# STM32MP23_CM33 register map
File version: 1.2
CPU: CM33 r0p1, little endian, MPU, FPU, vendor SysTick, 8 interrupt priority bits
Registers are 32-bit, read-write, reset 0x0 unless marked. A register's access mark holds for its fields unless they carry their own. Offsets are from the block's base; [hi:lo] are bit positions; {n}, {i} and the like mark numbered series; 'fields as' and 'values as' point back to an identical list.

## PWR — PWR register block
Base 0x44210000
Same registers: PWR_S 0x54210000
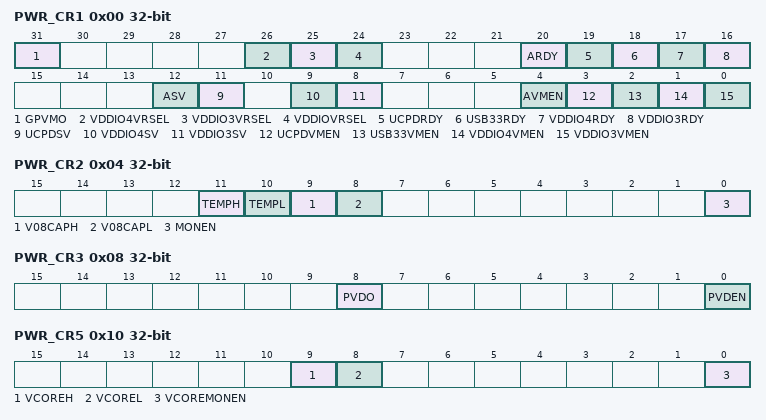
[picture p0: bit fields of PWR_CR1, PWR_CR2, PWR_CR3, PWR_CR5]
0x00 PWR_CR1 — PWR control register 1
  [31] GPVMO ro — Global peripheral voltage monitor output
    0=All enabled/valid independent power supplies are equal or higher than PVM threshold; 1=At least one enabled/valid independent power supply is lower than PVM threshold
  [26] VDDIO4VRSEL — VDDIO4 I/O voltage range selection
    0=3; 1=1
  [25] VDDIO3VRSEL — VDDIO3 I/O voltage range selection
    0=3; 1=1
  [24] VDDIOVRSEL — VDD I/O voltage range selection
    0=3; 1=1
  [20] ARDY ro — Vless thansub>DDA18ADC less than/sub>ready
    0=Vless thansub>DDA18ADCless than/sub> is below the threshold of the Vless thansub>DDA18ADCless than/sub> voltage monitor; 1=Vless thansub>DDA18ADCless than/sub> is equal or above the threshold of the Vless thansub>DDA18ADCless than/sub> voltage monitor
  [19] UCPDRDY ro — Vless thansub>DD33UCPD less than/sub>ready
    0=Vless thansub>DD33UCPDless than/sub> is below the threshold of the UCPD voltage monitor; 1=Vless thansub>DD33UCPDless than/sub> is equal or above the threshold of the UCPD voltage monitor
  [18] USB33RDY ro — Vless thansub>DD33USB less than/sub>ready
    0=Vless thansub>DD33USBless than/sub> is below the threshold of the USB33 voltage monitor; 1=Vless thansub>DD33USBless than/sub> is equal or above the threshold of the USB33 voltage monitor
  [17] VDDIO4RDY ro — Vless thansub>DDIO4 less than/sub>ready
    0=Vless thansub>DDIO4less than/sub> is below the threshold of the Vless thansub>DDIO4less than/sub> voltage monitor; 1=Vless thansub>DDIO4less than/sub> is equal or above the threshold of the Vless thansub>DDIO4less than/sub> voltage monitor
  [16] VDDIO3RDY ro — Vless thansub>DDIO3 less than/sub>ready
    0=Vless thansub>DDIO3less than/sub> is below the threshold of the Vless thansub>DDIO3less than/sub> voltage monitor; 1=Vless thansub>DDIO3less than/sub> is equal or above the threshold of the Vless thansub>DDIO3less than/sub> voltage monitor
  [12] ASV — Vless thansub>DDA18ADC less than/sub>independent supply valid
    0=Vless thansub>DDA18ADCless than/sub> is not present; 1=Vless thansub>DDA18ADCless than/sub> is valid
  [11] UCPDSV — Vless thansub>DD33UCPD less than/sub>independent supply valid
    0=Vless thansub>DD33UCPDless than/sub> is not present; 1=Vless thansub>DD33UCPDless than/sub> is valid
  [9] VDDIO4SV — Vless thansub>DDIO4 less than/sub>independent supply valid
    0=Vless thansub>DDIO4less than/sub> is not present; 1=Vless thansub>DDIO4less than/sub> is valid
  [8] VDDIO3SV — Vless thansub>DDIO3 less than/sub>independent supply valid
    0=Vless thansub>DDIO3less than/sub> is not present; 1=Vless thansub>DDIO3less than/sub> is valid
  [4] AVMEN — Vless thansub>DDA18ADC less than/sub>independent ADC voltage monitor enable
    0=Vless thansub>DDA18ADCless than/sub> voltage monitor disabled; 1=Vless thansub>DDA18ADCless than/sub> voltage monitor enabled
  [3] UCPDVMEN — Vless thansub>DD33UCPD less than/sub>independent UCPD voltage monitor enable
    0=Vless thansub>DD33UCPDless than/sub> voltage monitor disabled; 1=Vless thansub>DD33UCPDless than/sub> voltage monitor enabled
  [2] USB33VMEN — Vless thansub>DD33USB less than/sub>independent USB 33 voltage monitor enable
    0=Vless thansub>DD33USBless than/sub> voltage monitor disabled; 1=Vless thansub>DD33USBless than/sub> voltage monitor enabled
  [1] VDDIO4VMEN — Vless thansub>DDIO4 less than/sub>independent voltage monitor enable
    0=Vless thansub>DDIO4less than/sub> voltage monitor r disabled; 1=Vless thansub>DDIO4less than/sub> voltage monitor enabled
  [0] VDDIO3VMEN — Vless thansub>DDIO3 less than/sub>independent voltage monitor enable
    0=Vless thansub>DDIO3less than/sub> voltage monitor disabled; 1=Vless thansub>DDIO3less than/sub> voltage monitor enabled
0x04 PWR_CR2 — PWR control register 2
  [11] TEMPH ro — Monitored temperature level above high threshold
    0=Temperature below high threshold level, or monitor disabled; 1=Temperature equal or above high threshold level
  [10] TEMPL ro — Monitored temperature level above low threshold
    0=Temperature above low threshold level, or monitor disabled; 1=Temperature equal or below low threshold level
  [9] V08CAPH ro — Monitored Vless thansub>08CAPless than/sub> level above high threshold
    0=Vless thansub>08CAPless than/sub> level below high threshold level, or monitor disabled; 1=Vless thansub>08CAPless than/sub> level equal or above high threshold level
  [8] V08CAPL ro — Monitored Vless thansub>08CAPless than/sub> level above low threshold
    0=Vless thansub>08CAPless than/sub> level above low threshold level, or monitor disabled; 1=Vless thansub>08CAPless than/sub> level equal or below low threshold level
  [0] MONEN — Vless thansub>08CAPless than/sub> and temperature monitoring enable
    0=Vless thansub>08CAPless than/sub> and temperature monitoring disabled; 1=Vless thansub>08CAPless than/sub> and temperature monitoring enabled
0x08 PWR_CR3 — PWR control register 3
  [8] PVDO ro — Programmable voltage detector (PVD) output
    0=Voltage level on PVD_IN is equal or higher than the internal Vless thansub>REFINTless than/sub>; 1=Voltage level on PVD_IN is lower than the internal Vless thansub>REFINTless than/sub>
  [0] PVDEN — PVD enable
    0=PVD disabled; 1=PVD enabled
0x10 PWR_CR5 — PWR control register 5
  [9] VCOREH ro — Monitored Vless thansub>DDCOREless than/sub> level above high threshold
    0=Vless thansub>DDCOREless than/sub> level below high threshold level, or monitor disabled; 1=Vless thansub>DDCOREless than/sub> level equal or above high threshold level
  [8] VCOREL ro — Monitored Vless thansub>DDCOREless than/sub> level above low threshold
    0=Vless thansub>DDCOREless than/sub> level above low threshold level, or monitor disabled; 1=Vless thansub>DDCOREless than/sub> level equal or below low threshold level
  [0] VCOREMONEN — Vless thansub>DDCOREless than/sub> monitoring enable
    0=Vless thansub>DDCOREless than/sub> monitoring disabled; 1=Vless thansub>DDCOREless than/sub> monitoring enabled
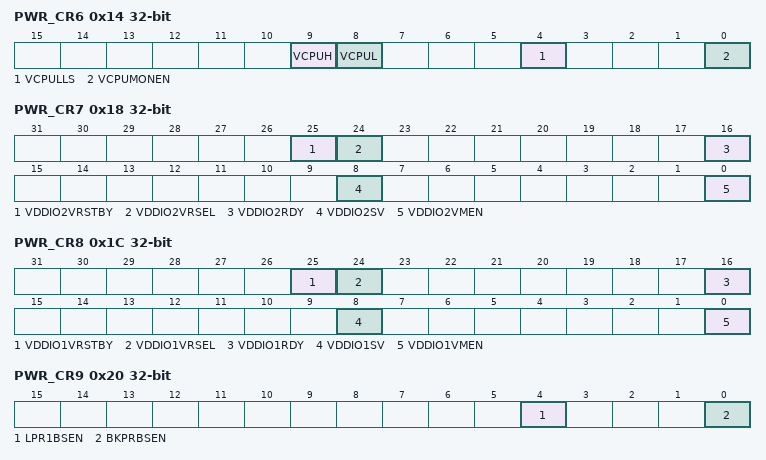
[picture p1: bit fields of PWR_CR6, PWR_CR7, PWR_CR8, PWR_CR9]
0x14 PWR_CR6 — PWR control register 6
  [9] VCPUH ro — Monitored Vless thansub>DDCPUless than/sub> level above high threshold
    0=Vless thansub>DDCPUless than/sub> level below high threshold level, or monitor disabled; 1=Vless thansub>DDCPUless than/sub> level equal or above high threshold level
  [8] VCPUL ro — Monitored Vless thansub>DDCPUless than/sub> level above low threshold
    0=Vless thansub>DDCPUless than/sub> level above low threshold level, or monitor disabled; 1=Vless thansub>DDCPUless than/sub> level equal or below low threshold level
  [4] VCPULLS — Vless thansub>DDCPUless than/sub> voltage detector low level selection
    0=VCPU low-voltage threshold 1 selected; 1=VCPU low-voltage threshold 2 selected (overdrive mode)
  [0] VCPUMONEN — Vless thansub>DDCPUless than/sub> monitoring enable
    0=Vless thansub>DDCPUless than/sub> monitoring disabled; 1=Vless thansub>DDCPUless than/sub> monitoring enabled
0x18 PWR_CR7 — PWR control register 7
  [25] VDDIO2VRSTBY — Vless thansub>DDIO2less than/sub> I/O voltage range Standby mode
    0=VDDIO2VRSEL not retained in Standby mode; 1=VDDIO2VRSEL retained in Standby mode
  [24] VDDIO2VRSEL — Vless thansub>DDIO2less than/sub> I/O voltage range selection
    0=3; 1=1
  [16] VDDIO2RDY ro — Vless thansub>DDIO2 less than/sub>ready
    0=Vless thansub>DDIO2less than/sub> is below the threshold of the Vless thansub>DDIO2less than/sub> voltage monitor; 1=Vless thansub>DDIO2less than/sub> is equal or above the threshold of the Vless thansub>DDIO2less than/sub> voltage monitor
  [8] VDDIO2SV — Vless thansub>DDIO2 less than/sub>Independent supply valid.
    0=Vless thansub>DDIO2less than/sub> is not present; 1=Vless thansub>DDIO2less than/sub> is valid
  [0] VDDIO2VMEN — Vless thansub>DDIO2 less than/sub>independent voltage monitor enable
    0=Vless thansub>DDIO2less than/sub> voltage monitor disabled; 1=Vless thansub>DDIO2less than/sub> voltage monitor enabled
0x1C PWR_CR8 — PWR control register 8
  [25] VDDIO1VRSTBY — Vless thansub>DDIO1less than/sub> I/O voltage range Standby mode
    0=VDDIO1VRSEL not retained in Standby mode; 1=VDDIO1VRSEL bit retained in Standby mode
  [24] VDDIO1VRSEL — Vless thansub>DDIO1less than/sub> I/O voltage range selection
    0=3; 1=1
  [16] VDDIO1RDY ro — Vless thansub>DDIO1 less than/sub>ready
    0=Vless thansub>DDIO1less than/sub> is below the threshold of the Vless thansub>DDIO1less than/sub> voltage monitor; 1=Vless thansub>DDIO1less than/sub> is equal or above the threshold of the Vless thansub>DDIO1less than/sub> voltage monitor
  [8] VDDIO1SV — Vless thansub>DDIO1 less than/sub>independent I/O supply valid
    0=Vless thansub>DDIO1less than/sub> is not present; 1=Vless thansub>DDIO1less than/sub> is valid
  [0] VDDIO1VMEN — Vless thansub>DDOI1 less than/sub>independent I/O voltage monitor enable
    0=Vless thansub>DDIO1less than/sub> voltage monitor disabled; 1=Vless thansub>DDIO1less than/sub> voltage monitor enabled
0x20 PWR_CR9 — PWR control register 9
  [4] LPR1BSEN — LPSRAM 1 backup supply enable
    0=LPSRAM1 backup supply disabled; 1=LPSRAM1 backup supply enabled
  [0] BKPRBSEN — Backup RAM backup supply enable
    0=BKPSRAM backup supply disabled; 1=BKPSRAM backup supply enabled
0x24 PWR_CR10 — PWR control register 10
  [1:0] RETRBSEN — Retention RAM backup supply enable
    0=RETRAM backup supply disabled; 1=RETRAM backup supply enabled in Standby and Vless thansub>BATless than/sub>; 2=RETRAM backup supply enabled only in Standby (memory content lost in Vless thansub>BATless than/sub> mode); 3=RETRAM backup supply enabled only in Standby (memory content lost in Vless thansub>BATless than/sub> mode)
0x28 PWR_CR11 — PWR control register 11
  [0] DDRRETDIS — DDR retention disable
    0=DDR self-refresh retention enabled; 1=DDR self-refresh retention disabled
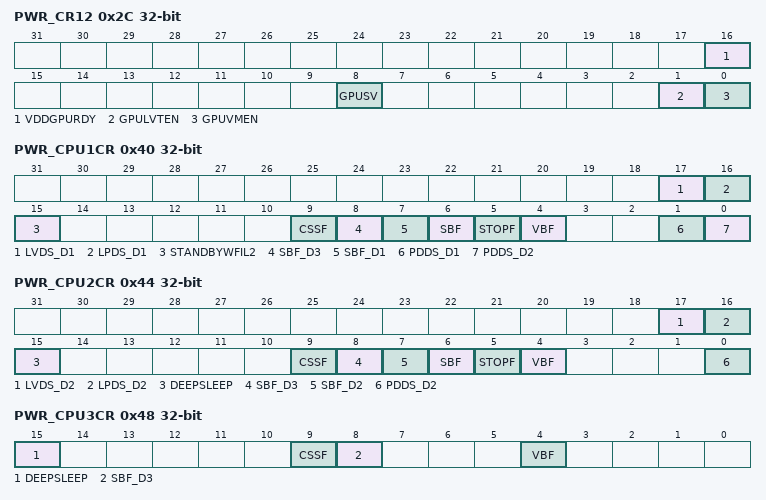
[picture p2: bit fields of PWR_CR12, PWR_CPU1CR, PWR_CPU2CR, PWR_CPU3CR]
0x2C PWR_CR12 — PWR control register 12
  [16] VDDGPURDY ro — Vless thansub>DDGPUless than/sub> ready
    0=Vless thansub>DDGPUless than/sub> is below the threshold of the Vless thansub>DDGPUless than/sub> voltage monitor (or the voltage monitor is disabled); 1=Vless thansub>DDGPUless than/sub> is equal or above the threshold of the Vless thansub>DDGPUless than/sub> voltage monitor
  [8] GPUSV — Vless thansub>DDGPU less than/sub>independent supply valid
    0=Vless thansub>DDGPUless than/sub> is not present; 1=Vless thansub>DDGPUless than/sub> is valid
  [1] GPULVTEN — Vless thansub>DDGPU less than/sub>low-voltage threshold enable
    0=Low-voltage threshold disabled; 1=Low-voltage threshold enabled
  [0] GPUVMEN — Vless thansub>DDGPUless than/sub> independent GPU voltage monitor enable
    0=Vless thansub>DDGPUless than/sub> voltage monitor disabled; 1=Vless thansub>DDGPUless than/sub> voltage monitor enabled
0x38 PWR_BDCR1 — PWR backup domain control register 1
  [0] DBD3P — Disable backup and D3 domains (including LPSRAM1/2/3) write protection
    0=Write access to backup and D3 domains disabled; 1=Write access to backup and D3 domains enabled
0x3C PWR_BDCR2 — PWR backup domain control register 2
  [0] DBP — Disable backup domain write protection
    0=Write access to backup domain disabled; 1=Write access to backup domain enabled
0x40 PWR_CPU1CR — PWR CPU1 control register
  [17] LVDS_D1 — Low-voltage Deepsleep LPLV-Stop mode selection for the D1 domain (DStop3)
    0=LP-Stop mode Vless thansub>DDCPU less than/sub>domainless thansub> less than/sub>supply reset level at same level as Run mode; 1=LPLV-Stop mode Vless thansub>DDCPU less than/sub>domain supply reset level at lower level than Run mode
  [16] LPDS_D1 — low-power Deepsleep Stop mode selection for the D1 domain (DStop2)
    0=Stop mode selected, external regulator kept in main power mode; 1=LP/LPLV-Stop mode selected, external regulator may enter low-power mode (low-power mode selection provided by LVDS_D1)
  [15] STANDBYWFIL2 ro — CPU1 system idle indication
    0=CPU1 system active; 1=CPU1 system idle
  [9] CSSF wo — Clear CPU1 STOPF, SBF_D1/D3, SBF, VBF and CPU2 SBF flags (Always read as 0)
    0=No effect; 1=Clear CPU1 (STOPF, SBF_D1/D3, SBF, VBF) and CPU2 SBF flags
  [8] SBF_D3 — D3 SStandby flag
    0=D3 domain has not been in SStandby mode; 1=D3 domain has been in SStandby mode
  [7] SBF_D1 ro — D1 DStandby flag
    0=D1 domain has not been in DStandby mode; 1=D1 domain has been in DStandby mode
  [6] SBF ro — System Standby flag
    0=System has not been in Standby mode; 1=System has been in Standby mode and system contents has been lost
  [5] STOPF ro — System Stop flag
    0=System has not been in Stop mode; 1=System has been in Stop mode, and the clock system has been stopped
  [4] VBF — Vless thansub>BATless than/sub> mode exit flag
    0=System has not been in Vless thansub>BATless than/sub> mode; 1=System has been in Vless thansub>BATless than/sub> mode
  [1] PDDS_D1 — D1 domain power-down Deepsleep selection
    0=DStop mode kept when CPU1 enters CStop; 1=DStandby mode allowed when CPU1 enters CStop
  [0] PDDS_D2 — D2 domain/system power-down Deepsleep selection
    0=Stop mode kept when CPU1 enters CStop; 1=Standby mode allowed when CPU1 enters CStop
0x44 PWR_CPU2CR — PWR CPU2 control register
  [17] LVDS_D2 — Low-voltage Deepsleep LPLV-Stop mode selection for the D2 domain/system
    0=LP-Stop mode Vless thansub>DDCORE less than/sub>domainless thansub> less than/sub>supply reset level at same level as Run mode; 1=LPLV-Stop mode Vless thansub>DDCORE less than/sub>domain supply reset level at lower level than Run mode
  [16] LPDS_D2 — low-power Deepsleep Stop mode selection for the D2 domain/syste.
    0=Stop mode selected, external regulator kept in main power mode (pwr_lp=1); 1=LP/LPLV-Stop mode selected, external regulator may enter low-power mode (pwr_lp = 0) (low-power mode selection provided by LVDS_D2)
  [15] DEEPSLEEP ro — CPU2 system idle indication
    0=CPU2 system active; 1=CPU2 system idle
  [9] CSSF wo — Clear CPU2 STOPF, SBF_D2/D3, SBF, VBF and CPU1 SBF flags (Always read as 0)
    0=No effect; 1=Clear CPU2 (STOPF, SBF_D2/D3, SBF, VBF) and CPU1 SBF flags
  [8] SBF_D3 — D3 SStandby flag
    values as PWR_CPU1CR.SBF_D3
  [7] SBF_D2 ro — D2 Standby flag
    0=D2 domain has not been in Standby mode; 1=D2 domain has been in Standby mode
  [6] SBF ro — System Standby flag
    0=System has not been in Standby mode; 1=System has been in Standby mode, system contents has been lost
  [5] STOPF ro — System Stop flag
    values as PWR_CPU1CR.STOPF
  [4] VBF — Vless thansub>BATless than/sub> exit flag
    values as PWR_CPU1CR.VBF
  [0] PDDS_D2 — D2 domain/system power-down Deepsleep selection
    0=Stop mode kept when CPU2 enters CStop; 1=Standby mode allowed when CPU2 enters CStop
0x48 PWR_CPU3CR — PWR CPU3 control register
  [15] DEEPSLEEP ro — CPU3 system idle indication
    0=CPU3 active; 1=CPU3 idle
  [9] CSSF wo — Clear CPU3 SBF_D3 and VBF flags (Always read as 0)
    0=No effect; 1=Clear CPU3 SBF_D3 and VBF flags
  [8] SBF_D3 ro — D3 SStandby flag
    values as PWR_CPU1CR.SBF_D3
  [4] VBF ro — Vless thansub>BATless than/sub> exit flag
    values as PWR_CPU1CR.VBF
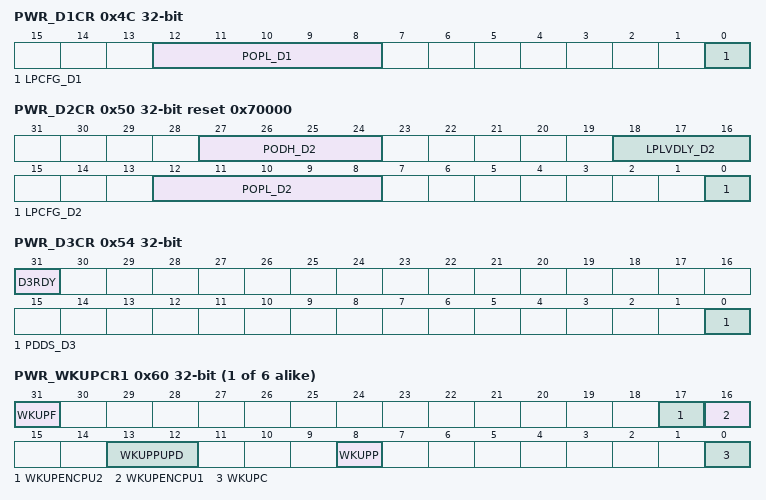
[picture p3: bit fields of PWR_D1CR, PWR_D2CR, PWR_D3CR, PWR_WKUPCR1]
0x4C PWR_D1CR — PWR D1 control register
  [12:8] POPL_D1 — pwr_cpu_on pulse low configuration
    0=No guaranteed minimum low time; 1=~ 1 ms guaranteed minimum low time (1 x 32 LSI cycles); 2=~ 2 ms guaranteed minimum low time (2 x 32 LSI cycles); 31=~ 31 ms guaranteed minimum low time
  [0] LPCFG_D1 — PWR_CPU_ON pin configuration
    0=PWR_CPU_ON pin signals DStandby mode (PWR_CPU_ON=1 in DRun, DStop1/2/3, and=0 in DStandby) (pwr_cpu_on); 1=PWR_CPU_ON pin signals DStandby and DStop2/3 modes (PWR_CPU_ON = 1 in DRun, DStop1, and=0 in DStop2/3 and DStandby) (pwr_cpu_onlp)
0x50 PWR_D2CR reset 0x70000 — PWR D2 control register
  [27:24] PODH_D2 — pwr_on delay high configuration
    0=No delay; 1=~ 1 ms delay (1 x 32 LSI cycles); 2=~ 2 ms delay (2 x 32 LSI cycles); 15=~ 15 ms delay (15 x 32 LSI cycles)
  [18:16] LPLVDLY_D2 — LPLV delay value
    0=~187 us delay (1 x 6 LSI cycles); 1=~375 us delay (2 x 6 LSI cycles); 2=~562 us delay (3 x 6 LSI cycles); 7=~1
  [12:8] POPL_D2 — pwr_on pulse low configuration
    0=No guaranteed minimum low time; 1=~ 1 ms guaranteed minimum low time (1 x 32 LSI cycles); 2=~ 2 ms guaranteed minimum low time (2 x 32 LSI cycles); 31=~ 31 ms guaranteed minimum low time (31 x 32 LSI cycles)
  [0] LPCFG_D2 — PWR_ON pin configuration
    0=PWR_ON pin signals Standby (PWR_ON = 1 in Run, Stop1/2, LP-Stop1/2, LPLV-Stop1/2, and = 0 in Standby1/2) (pwr_on); 1=PWR_ON pin signals Standby, LP-Stop, and LPLV-Stop modes (PWR_ON = 1 in Run, Stop1/2, and = 0 in LP-Stop1/2, LPLV-Stop1/2 and Standby1/2) (pwr_onlp)
0x54 PWR_D3CR — PWR D3 control register
  [31] D3RDY ro — D3 domain supply ready
    0=D3 domain not ready; 1=D3 domain ready
  [0] PDDS_D3 — D3 domain power-down Deepsleep selection
    0=SStop mode kept when system enters Standby; 1=SStandby mode allowed when system enters Standby
{0x5C+4i} PWR_WKUPCR{i} (i=1..6) — PWR wake-up control register {i}
  [31] WKUPF ro — Wake-up flag for WKUPx pin before enable
    0=No wake-up event occurred; 1=A wake-up event was received from WKUPx pin
  [17] WKUPENCPU2 — Enable WKUPx pin and interrupt for CPU2
    0=An event on WKUPx pin does not wake up the system from Standby or Stop, nor generates an interrupt to CPU2; 1=A rising or falling edge on WKUPx pin wakes up the system from Standby or Stop, and generates an interrupt to CPU2
  [16] WKUPENCPU1 — Enable WKUPx pin and interrupt for CPU1
    0=An event on WKUPx pin does not wake up the system from Standby or Stop, nor generates an interrupt to CPU1; 1=A rising or falling edge on WKUPx pin wakes up the system from Standby or Stop, and generates an interrupt to CPU1
  [13:12] WKUPPUPD — Wake-up pull configuration for WKUPx pin
    0=No pulls; 1=Pull-up; 2=Pull-down
  [8] WKUPP — Wake-up polarity bit for WKUPx pin
    0=High-level detection (rising edge); 1=Low-level detection (falling edge)
  [0] WKUPC wo — Clear wake-up flag for WKUPx pin
    0=No effect; 1=Clear WKUPF inPWR_WKUPCRx
0x98 PWR_D3WKUPENR — PWR D3 wake-up enable register
  [0] TAMP_WKUPEN_D3 — Enable D3 domain wake-up on tamper event in Vless thansub>BATless than/sub> mode
    0=A tamper event on D3WKUP pin does not wake up the D3 domain from SStandby in Vless thansub>BATless than/sub>; 1=A tamper event on D3WKUP pin wakes up the D3 domain from SStandby in Vless thansub>BATless than/sub>
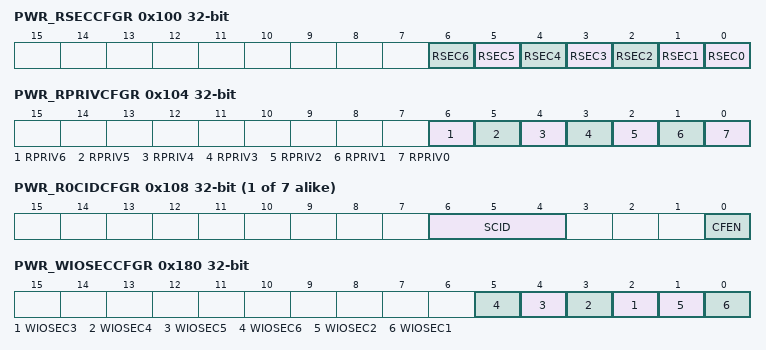
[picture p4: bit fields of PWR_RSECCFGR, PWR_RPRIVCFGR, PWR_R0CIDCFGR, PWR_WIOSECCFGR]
0x100 PWR_RSECCFGR — PWR resource secure configuration register
  [n] RSEC{n} (n=1..6) — Secure attribute reference for the local resource number {n}
  [0] RSEC0 — Secure attribute reference for the local resource number 0
    0=The local resource number 0 is non-secure; 1=The local resource number 0 is secure only
0x104 PWR_RPRIVCFGR — PWR resource privileged configuration register
  [6] RPRIV6 — Privileged attribute reference for the local resource number 6
  [5] RPRIV5 — Privileged attribute reference for the local resource number 5
  [4] RPRIV4 — Privileged attribute reference for the local resource number 4)
  [3] RPRIV3 — Privileged attribute reference for the local resource number 3
  [2] RPRIV2 — Privileged attribute reference for the local resource number 2
  [1] RPRIV1 — Privileged attribute reference for the local resource number 1
  [0] RPRIV0 — Privileged attribute reference for the local resource number 0
    0=The local resource number 0is unprivileged; 1=The local resource number 0is privileged only
{0x108+4i} PWR_R{i}CIDCFGR (i=0..6) — PWR resource {i} CID configuration register
  [6:4] SCID — Static compartment identifier
  [0] CFEN — Compartment ID filter enable
    0=Compartment-based filtering is disabled for resource number x; 1=Compartment-based filtering is enabled for resource number x
0x180 PWR_WIOSECCFGR — PWR WIO secure configuration register
  [n-1] WIOSEC{n} (n=3..6) — Secure attribute reference for the wake-up I/O {n}
  [1] WIOSEC2 — Secure attribute reference for the wake-up I/O 2)
  [0] WIOSEC1 — Secure attribute reference for the wake-up I/O 1
    0=The wake-up I/O 1 is non-secure; 1=The wake-up I/O 1 is secure only
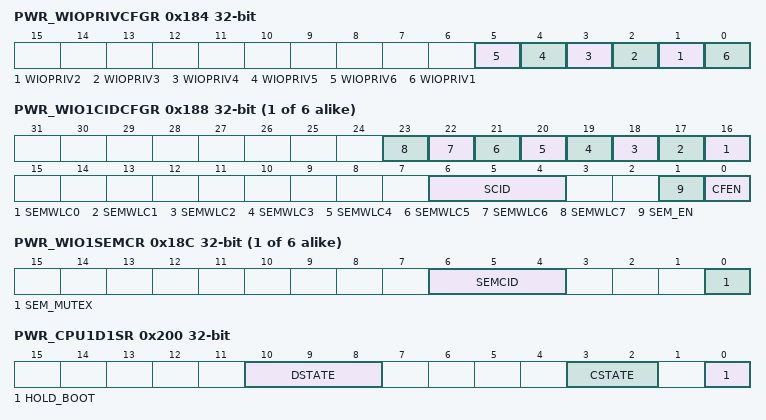
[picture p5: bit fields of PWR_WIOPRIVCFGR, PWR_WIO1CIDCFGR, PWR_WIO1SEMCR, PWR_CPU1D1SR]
0x184 PWR_WIOPRIVCFGR — PWR WIO privileged configuration register
  [n-1] WIOPRIV{n} (n=2..6) — Privileged attribute reference for the wake-up I/O {n}
  [0] WIOPRIV1 — Privileged attribute reference for the wake-up I/O 1
    0=The wake-up I/O 1 is unprivileged; 1=The wake-up I/O 1 is privileged only
{0x180+8i} PWR_WIO{i}CIDCFGR (i=1..6) — PWR WIO {i} CID configuration register
  [n+16] SEMWLC{n} (n=0..7) — Semaphore CID {n} enable
    0=CID {n} agent disabled to take the semaphore; 1=CID {n} agent enabled to take the semaphore
  [6:4] SCID — Static CID
  [1] SEM_EN — Semaphore enable
    0=Wake-up I/O x access granted only if CID of the access equals to SCID; 1=Wake-up I/O x access granted only if SEM_MUTEX=1 and CID of the access equals to SEMCID in PWR_WIOxSEMCR
  [0] CFEN — CID filtering enable
    0=Compartment-based filtering defined in PWR_WIOxCIDCFGR and optionally PWR_WIOxSEMCR is disabled for wake-up I/O x; 1=Compartment-based filtering defined in PWR_WIOxCIDCFGR and optionally PWR_WIOxSEMCR is enabled for wake-up I/O x
{0x184+8i} PWR_WIO{i}SEMCR (i=1..6) — PWR WIO {i} semaphore control register
  [6:4] SEMCID ro — Semaphore current CID
  [0] SEM_MUTEX — Semaphore mutex
0x200 PWR_CPU1D1SR ro — PWR CPU1 status register
  [10:8] DSTATE — D1 domain state status
    0=DRun; 1=DStop1; 2=DStop2; 3=DStop3; 4=DStandby
  [3:2] CSTATE — CPU1 cluster state status
    0=CPU1 in reset; 1=CPU1 in CRun; 2=CPU1 in CSleep; 3=CPU1 in CStop
  [0] HOLD_BOOT — CPU1 HOLD_BOOT status flag.
    0=CPU1 allowed to boot; 1=CPU1 maintained in HOLD_BOOT state by hardware
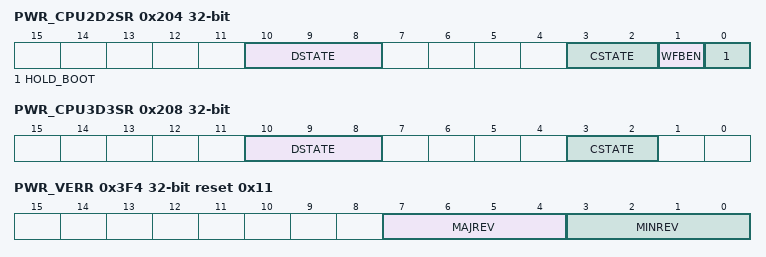
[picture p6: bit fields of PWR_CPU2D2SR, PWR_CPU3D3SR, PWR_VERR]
0x204 PWR_CPU2D2SR ro — PWR CPU2 status register
  [10:8] DSTATE — System/D2 state status
    0=Run; 1=Stop; 2=LP-Stop; 3=LPLV-Stop; 4=Standby; 5=Vless thansub>BATless than/sub>
  [3:2] CSTATE — CPU2 cluster state status flag
    0=CPU2 in reset; 1=CPU2 in CRun; 2=CPU2 in CSleep; 3=CPU2 in CStop
  [1] WFBEN — CPU2 wait-for-boot enable status flag
    0=CPU2 is not in wait-for-boot enable state (bit set at 0 in legacy boot mode); 1=CPU2 is in wait-for-boot enable state
  [0] HOLD_BOOT — CPU2 HOLD_BOOT status flag
    0=CPU2 is allowed to boot; 1=CPU2 is maintained in HOLD_BOOT state by hardware
0x208 PWR_CPU3D3SR ro — PWR CPU3 status register
  [10:8] DSTATE — D3 state status.
    0=SRun1; 1=SRun2; 2=SRun3; 3=SStop1; 4=SStop2; 5=SStandby (only accessible in debug Standby mode)
  [3:2] CSTATE — CPU3 cluster state status flag
    0=CPU3 in reset; 1=CPU3 in CRun; 2=CPU3 in CSleep; 3=CPU3 in CStop
0x3F4 PWR_VERR ro reset 0x11 — PWR VER register
  [7:4] MAJREV — Major revision number
  [3:0] MINREV — Minor revision number
0x3F8 PWR_IPIDR ro reset 0x10003 — PWR identifier register
  [31:0] ID — Identifier of the PWR
0x3FC PWR_SIDR ro reset 0xA3C5DD01 — PWR size identification register
  [31:0] SID — Decoding space is 1 Kbyte.
